# RA2A1 register map
Vendor: Renesas Electronics Corporation; Series: RA2; File version: 1.1
CPU: other r1p0, little endian, MPU, no FPU, VTOR, 2 interrupt priority bits
Registers are 8-bit, read-write, reset 0x0 unless marked. A register's access mark holds for its fields unless they carry their own. Offsets are from the block's base; [hi:lo] are bit positions; {n}, {i} and the like mark numbered series.

## POEG — Port Output Enable Module for GPT
Base 0x40042000
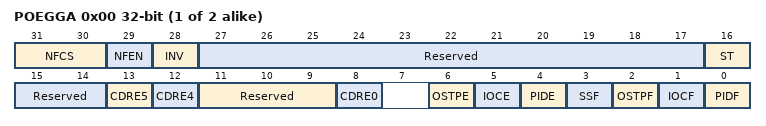
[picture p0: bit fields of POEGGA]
0x00 POEGG{x} (x=A,B; step 0x100) 32-bit — POEG Group {x} Setting Register
  [31:30] NFCS — Noise Filter Clock Select
    0=Sampling GTETRG pin input level for three times in every PCLKB; 1=Sampling GTETRG pin input level for three times in every PCLKB /8; 2=Sampling GTETRG pin input level for three times in every PCLKB /32; 3=Sampling GTETRG pin input level for three times in every PCLKB /128
  [29] NFEN — Noise Filter Enable
    0=Filtering noise disabled; 1=Filtering noise enabled
  [28] INV — GTETRG Input Reverse
    0=GTETRG Input; 1=GTETRG Input Reversed
  [27:17] Reserved — These bits are read as 00000000000. The write value should be 00000000000.
  [16] ST ro — GTETRG Input Status Flag
    0=GTETRG input after filtering is 0; 1=GTETRG input after filtering is 1
  [15:14] Reserved — These bits are read as 00. The write value should be 00.
  [13] CDRE5 — ACMP_LP1 EnableNote: Can be modified only once after a reset.
    0=Disable output-disable request from ACMPLP1; 1=Enable output-disable request from ACMPLP1
  [12] CDRE4 — ACMP_LP0 EnableNote: Can be modified only once after a reset.
    0=Disable output-disable request from ACMPLP0; 1=Enable output-disable request from ACMPLP0
  [11:9] Reserved — These bits are read as 000. The write value should be 000.
  [8] CDRE0 — ACMP_HS0 EnableNote: Can be modified only once after a reset.
    0=Disable output-disable request from ACMPHS0; 1=Enable output-disable request from ACMPHS0
  [6] OSTPE — Oscillation Stop Detection EnableNote: Can be modified only once after a reset.
    0=A output-disable request from the oscillation stop detection disabled; 1=A output-disable request from the oscillation stop detection enabled
  [5] IOCE — Real Time Overcurrent EnableNote: Can be modified only once after a reset.
    0=A output-disable request from GPT disable request or comparator interrupt disabled; 1=A output-disable request from GPT disable request or comparator interrupt enabled
  [4] PIDE — Port Input Detection EnableNote: Can be modified only once after a reset.
    0=A output-disable request from the GTETRG pins disabled; 1=A output-disable request from the GTETRG pins enabled
  [3] SSF — Software Stop Flag
    0=A output-disable request from software has not been generated; 1=A output-disable request from software has been generated
  [2] OSTPF write-0-clears read-modifies — Oscillation Stop Detection Flag
    0=A output-disable request from the oscillation stop detection has not been generated; 1=A output-disable request from the oscillation stop detection has been generated
  [1] IOCF write-0-clears read-modifies — Real Time Overcurrent Detection Flag
    0=No output-disable request from the GPT, the ACMPHS or the ACMPLP occurred; 1=Output-disable request from the GPT, the ACMPHS or the ACMPLP occurred
  [0] PIDF write-0-clears read-modifies — Port Input Detection Flag
    0=A output-disable request from the GTETRG pin has not been generated; 1=A output-disable request from the GTETRG pin has been generated

## FCACHE — Flash Cache
Base 0x4001C000
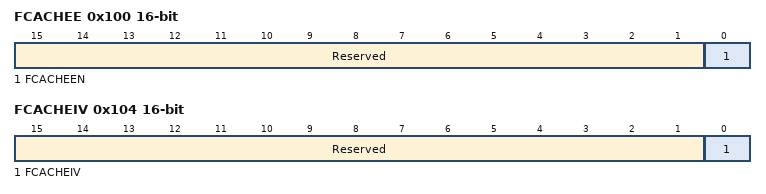
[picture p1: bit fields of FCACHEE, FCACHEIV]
0x100 FCACHEE 16-bit — Flash Cache Enable Register
  [15:1] Reserved — These bits are read as 000000000000000. The write value should be 000000000000000.
  [0] FCACHEEN — FCACHE Enable
    0=FCACHE is disabled; 1=FCACHE is enabled
0x104 FCACHEIV 16-bit — Flash Cache Invalidate Register
  [15:1] Reserved — These bits are read as 000000000000000. The write value should be 000000000000000.
  [0] FCACHEIV write-1-sets read-modifies — FCACHE Invalidation
    0=(Read)not in progress / (Write) no effect; 1=(Read)in progress /(Write) Starting Cache Invalidation

## PORT0 — Port 0 Control Registers
Base 0x40040000
Same registers: PORT3 0x40040060, PORT4 0x40040080, PORT5 0x400400A0, PORT9 0x40040120
0x00 PCNTR1 32-bit — Port Control Register 1
0x00 PODR 16-bit (alternate view of PCNTR1) — Output data register
0x02 PDR 16-bit (alternate view of PCNTR1) — Direction register
0x04 PCNTR2 32-bit ro (reset mask 0xFFFF0000) — Port Control Register 2
0x06 PIDR 16-bit ro reset not defined (alternate view of PCNTR2) — Input data register
0x08 PCNTR3 32-bit wo — Port Control Register 3
0x08 PORR 16-bit wo (alternate view of PCNTR3) — Output reset register
0x0A POSR 16-bit wo (alternate view of PCNTR3) — Output set register

## PORT1 — Port 1 Control Registers
Base 0x40040020
Same registers: PORT2 0x40040040
Registers as PORT0; these are added or differ:
0x04 EIDR 16-bit ro (alternate view of PCNTR2) — Event input data register
0x0C PCNTR4 32-bit — Port Control Register 4
0x0C EORR 16-bit (alternate view of PCNTR4) — Event output reset register
0x0E EOSR 16-bit (alternate view of PCNTR4) — Event output set register

## PMISC — Miscellaneous Port Control Register
Base 0x40040D00
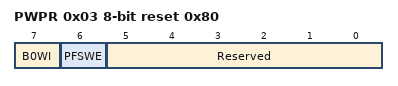
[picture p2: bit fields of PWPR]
0x03 PWPR reset 0x80 — Write-Protect Register
  [7] B0WI — PFSWE Bit Write Disable
    0=Writing to the PFSWE bit is enabled; 1=Writing to the PFSWE bit is disabled
  [6] PFSWE — PFS Register Write Enable
    0=Writing to the PFS register is disabled; 1=Writing to the PFS register is enabled
  [5:0] Reserved — These bits are read as 000000. The write value should be 000000.
